# A31C15x register map
Vendor: ABOV Semiconductor Co., Ltd.; File version: 1.0
CPU: CM0PLUS r0p1, little endian, no MPU, no FPU, VTOR, 2 interrupt priority bits
Registers are 32-bit, read-write, reset 0x0 unless marked. A register's access mark holds for its fields unless they carry their own. Offsets are from the block's base; [hi:lo] are bit positions; {n}, {i} and the like mark numbered series.

## SPI0 — Serial Peripheral Interface Bus
Base 0x40009000
Same registers: SPI1 0x40009100
0x00 TDR wo — SPI n Transmit Data Register
  [16:0] TDR — Transmit Data Bit
0x00 RDR ro — SPI n Received Data Register
  [16:0] RDR — Received Data Bit
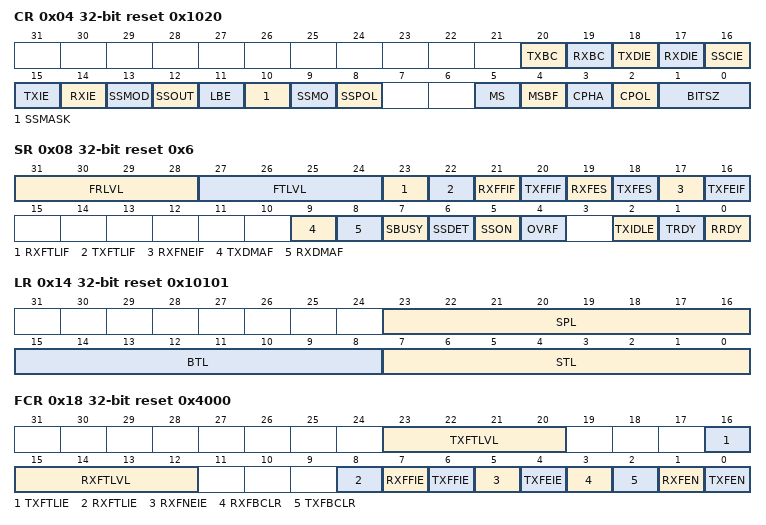
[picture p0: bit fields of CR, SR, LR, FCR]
0x04 CR reset 0x1020 — SPI Control Register
  [20] TXBC wo — Tx Buffer Clear Bit
  [19] RXBC wo — Rx Buffer Clear Bit
  [18] TXDIE — DMA Tx Complete Interrupt Enable Bit
  [17] RXDIE — DMA Rx Complete Interrupt Enable Bit
  [16] SSCIE — SS Edge Changed Interrupt Enable Bit
  [15] TXIE — Transmit Interrupt Enable Bit
  [14] RXIE — Received Interrupt Enable Bit
  [13] SSMOD — SS Auto/Manual Output Selection Bit in Master Mode
  [12] SSOUT — SS Output Signal Control Bit
  [11] LBE — Loop-back Mode Selection Bit in Master Mode
  [10] SSMASK — SS Signal Masking in Slave Mode
  [9] SSMO — SS Output Signal Enable Bit
  [8] SSPOL — SS Signal Polarity Selection Bit
  [5] MS — Master/Slave Selection Bit
  [4] MSBF — MSB/LSB Transmit Advance Selection Bit
  [3] CPHA — SPI Clock Phase Bit
  [2] CPOL — SPI Clock Polarity Bit
  [1:0] BITSZ — Transmit/Receive Bit Size Selection Bit
    0=8_BIT (Size is 8 bit); 1=9_BIT (Size is 9 bit); 2=16_BIT (Size is 16 bit); 3=17_BIT (Size is 17 bit)
0x08 SR reset 0x6 — SPI n Status Register
  [31:28] FRLVL ro — FIFO Reception Level
  [27:24] FTLVL ro — FIFO Transmit Level
  [23] RXFTLIF — Receive FIFO trigger level interrupt flag
  [22] TXFTLIF — Transmit FIFO trigger level interrupt flag
  [21] RXFFIF — Receive FIFO full interrupt flag
  [20] TXFFIF — Transmit FIFO full interrupt flag
  [19] RXFES ro — Receive FIFO empty status
  [18] TXFES ro — Transmit FIFO empty status
  [17] RXFNEIF — Receive FIFO not empty interrupt flag
  [16] TXFEIF — Transmit FIFO empty interrupt flag
  [9] TXDMAF — DMA Transmit Operation Complete Flag
  [8] RXDMAF — DMA Received Operation Complete Flag
  [7] SBUSY ro — Transmit/Received Operating Flag
  [6] SSDET — SS Signal Rising or Falling Edge Detected Flag
  [5] SSON — SS Signal Status Flag
  [4] OVRF — Received Overrun Error Flag
  [2] TXIDLE ro — Transmit Operating Flag
  [1] TRDY ro — Transmit Buffer Empty Flag
  [0] RRDY ro — Received Buffer Empty Flag
0x0C BR reset 0xFFFF — SPI n Baud Rate Register
  [15:0] BR — Baud Rate Setting Bit
0x10 EN — SPI n Enable Register
  [0] ENABLE — SPI Enable Bit
0x14 LR reset 0x10101 — SPI n Delay Length Register
  [23:16] SPL — SPI STOP Length Value Bit
  [15:8] BTL — SPI Burst Length Value Bit
  [7:0] STL — SPI Start Length Value Bit
0x18 FCR reset 0x4000 — SPI n FIFO Control Register
  [23:20] TXFTLVL — Transmit FIFO trigger level select bit.
  [16] TXFTLIE — Transmit FIFO trigger level interrupt enable bit.
  [15:12] RXFTLVL — Receive FIFO trigger level select bit.
  [8] RXFTLIE — Receive FIFO trigger level interrupt enable bit.
  [7] RXFFIE — Receive FIFO full interrupt enable bit.
  [6] TXFFIE — Transmit FIFO full interrupt enable bit.
  [5] RXFNEIE — Receive FIFO not empty interrupt enable bit.
  [4] TXFEIE — Transmit FIFO empty interrupt enable bit.
  [3] RXFBCLR wo — Receive FIFO buffer clear bit. (auto-clear)
  [2] TXFBCLR wo — Transmit FIFO buffer clear bit. (auto-clear)
  [1] RXFEN — Receive FIFO enable bit.
  [0] TXFEN — Transmit FIFO enable bit.
0x1C FTDR — SPI n FIFO Transmit Data Register
  [16:0] FTDR
0x20 FRDR — SPI n FIFO Receive Data Register
  [16:0] FRDR — SPI FIFO Receive Data Register

## I2C0 — Inter-Integrated Circuit
Base 0x4000A000
Same registers: I2C1 0x4000A100, I2C2 0x4000A200
0x00 DR reset 0xFF — I2C data register
  [7:0] ICDR — In transmit mode, the data stored in this register is outputted from pin SDA in the serial data line. In receive mode, data received at pin SDA is stored in this register; hence, the stored data is loaded by reading this register
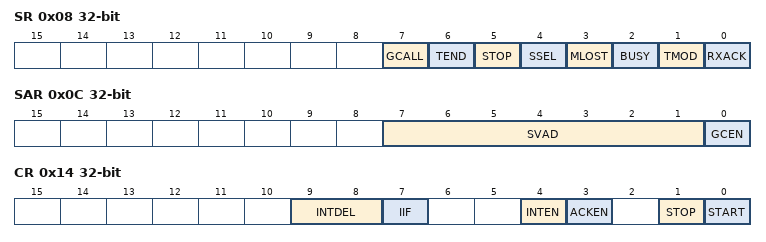
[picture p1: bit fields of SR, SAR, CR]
0x08 SR — I2C status register
  [7] GCALL — This bit signifies different things, depending on whether the I2C is in master or slave mode.
  [6] TEND — One-byte transmit end flag
  [5] STOP — Stop flag
  [4] SSEL — Slave flag
  [3] MLOST — Mastership loss flag
  [2] BUSY ro — Bus busy flag
  [1] TMOD ro — Transmit / receive mode flag
  [0] RXACK — Rx ACK flag
0x0C SAR — I2C slave address register
  [7:1] SVAD — 7-bit slave address
  [0] GCEN — Whether to enable or disable general call
0x14 CR — I2C Control Register
  [9:8] INTDEL — Internal delay between address and data transfers (Or between two data transfers)
    0=1_ICnSCLL (Delay = 1*ICnSCLL); 1=2_ICnSCLL (Delay = 2*ICnSCLL); 2=4_ICnSCLL (Delay = 4*ICnSCLL); 3=8_ICnSCLL (Delay = 8*ICnSCLL)
  [7] IIF ro — Interrupt flag
  [4] INTEN — Whether to enable or disable interrupts
  [3] ACKEN — Whether to enable or disable ACK in receive mode
  [1] STOP — Whether to enable or disable stop
  [0] START — Transmission start in master mode
0x18 SCLL reset 0xFFFF — I2C SCL low duration register
  [15:0] SCLL — SCL low duration value
0x1C SCLH reset 0xFFFF — I2C SCL high duration register
  [15:0] SCLH — SCL high duration value
0x20 SDH reset 0x7FFF — I2C SDA hold register
  [14:0] SDH — SDA hold time value

## CMP0 — Comparator
Base 0x4000B380
Same registers: CMP1 0x4000B390
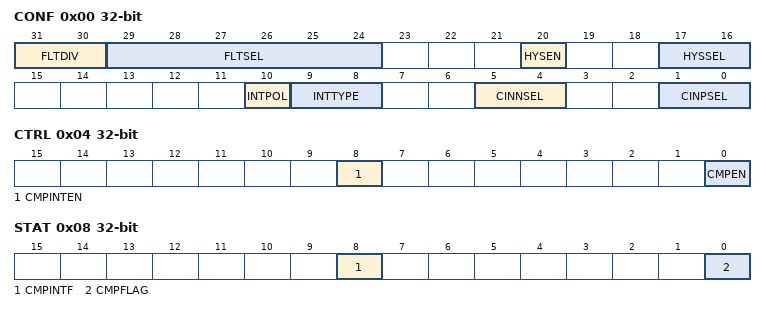
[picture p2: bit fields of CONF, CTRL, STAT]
0x00 CONF — Comparator Configure Register
  [31:30] FLTDIV — Digital filter clock divider
  [29:24] FLTSEL — Digital filter count
  [20] HYSEN — Hysteresis enable bit
  [17:16] HYSSEL — Hysteresis selection bit
    0=Hys_40mV (40mV Hysteresis); 1=Hys_80mV (80mV Hysteresis); 2=Hys_120mV (120mV Hysteresis); 3=Hys_160mV (160mV Hysteresis)
  [10] INTPOL — Interrupt polarity selection bit
    0=Low (Low (Falling)); 1=High (Rising)
  [9:8] INTTYPE — Interrupt type selection bit
    0=Disable; 1=Level; 2=Single_edge; 3=Both_edge
  [5:4] CINNSEL — Reference (input -) selection bit
    0=External Reference; 2=Ground; 3=Internal Reference
  [1:0] CINPSEL — Source (input +) selection bit
    0=CPnA (CMP0 : CP0A, CMP1 : CP1A); 1=CPB; 2=Ground; 3=Internal Reference
0x04 CTRL — Comparator Control Register
  [8] CMPINTEN — Comparator interrupt enable bit
  [0] CMPEN — Comparator enable bit
0x08 STAT — Comparator Status Register
  [8] CMPINTF — Comparator interrupt flag bit
    0=Not_occurred (Interrupt not occurred); 1=occurred (Interrupt occurred (writing '1' to the bit clears it to '0'))
  [0] CMPFLAG ro — Comparator output status
    0=Low; 1=High

## DBCR — Comparator Debounce
Base 0x4000B3C0
0x00 DBCR reset 0x4000 — Comparator Debounce Control Register
  [0] DBEN wo — All comparator output pin debounce filter enable bit
    0=Disable (All comparator output pin debounce filter disable); 1=Enable (All comparator output pin debounce filter enable)

## CRC — Cyclic Redundancy Check calculation module
Base 0x40082000
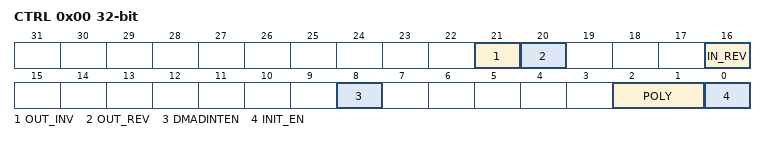
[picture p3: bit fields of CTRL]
0x00 CTRL — CRC control register
  [21] OUT_INV — Whether to enable or disable CRC output data inversion
  [20] OUT_REV — Reverse CRC output data
  [16] IN_REV — Reverse CRC input data
  [8] DMADINTEN — Whether to enable or disable the DMA done interrupt
  [2:1] POLY — Polynomial selection bit
    0=CRC32 (CRC32 (0x04C1_1DB7)); 1=CRC16_USB (CRC16_USB (0x8005)); 2=CRC16_CCITT (CRC16_CCITT (0x1021)); 3=CRC8_CCITT (CRC8_CCITT (0x07))
  [0] INIT_EN wo — Whether or not to apply the CRC initial value register (auto clear)
0x04 INIT reset 0xFFFFFFFF — CRC Init Data Register
  [31:0] INIT_EN — CRC Initial Value
0x08 IDR wo — CRC Input Data Register
  [31:0] IDR — CRC input data bits
0x08 ODR ro reset 0xFFFFFFFF — CRC Output Data Register
  [31:0] ODR — CRC output data bits
0x0C STAT — CRC Status Register
  [8] DMADINT — DMA Done Interrupt Flag Bit

## DBGMCU — Debug MCU Control Register
Base 0x4000F020
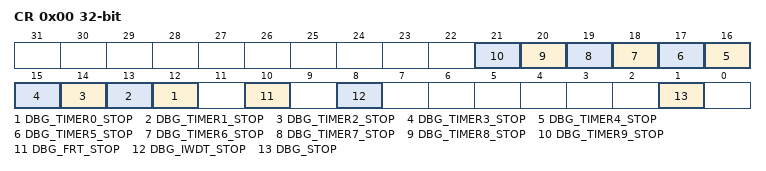
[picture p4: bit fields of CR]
0x00 CR — Debug MCU Register
  [n+12] DBG_TIMER{n}_STOP (n=0..9) — Debug TIMER{n} stopped when core is halted
  [10] DBG_FRT_STOP — Debug FRT stopped when core is halted.
  [8] DBG_IWDT_STOP — Debug independent watchdog stopped when core is halted.
  [1] DBG_STOP — Debug stop mode.
